# ADSP-2183xW_LPC register map
Vendor: Analog Devices; Series: ADSP-2183xW_LPC; File version: 3.0.3.517
CPU: 
Registers are 32-bit, read-write, reset 0x0 unless marked. A register's access mark holds for its fields unless they carry their own. Offsets are from the block's base; [hi:lo] are bit positions; {n}, {i} and the like mark numbered series.

## WDOG0 — Watchdog Timer Unit
Base 0x31008000
Same registers: WDOG1 0x31008800, WDOG2 0x31009000
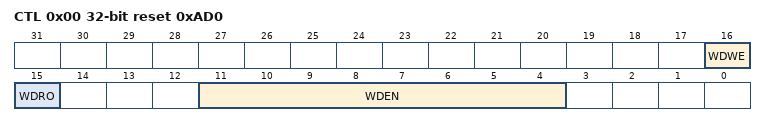
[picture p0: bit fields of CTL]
0x00 CTL reset 0xAD0 — Control Register
  [16] WDWE — Watchdog Window Event
  [15] WDRO — Watch Dog Rollover
  [11:4] WDEN — Watch Dog Enable
0x04 CNT — Count Register
  [31:0] VALUE range 0x00000000..0xFFFFFFFF — Count Value
0x08 STAT — Watchdog Timer Status Register
  [31:0] VALUE range 0x00000000..0xFFFFFFFF — Current Count Value (Status)
0x0C WIN reset 0xFFFFFFFF — Watchdog Timer Window Register
  [31:0] VALUE range 0x00000000..0xFFFFFFFF — Window Value

## OTPC0 — OTP Memory Controller
Base 0x31011000
0x04 STAT — OTP Status Register
  [14:13] ADDRERR ro — OTP Address Error
0x2C SECU_STATE reset 0x1 — OTP Security State Register
  [0] PARTLOCK ro — Part Locked
    0=OPEN (OPEN part); 1=LOCKED (Locked part)

## HADC0 — Housekeeping ADC
Base 0x31016000
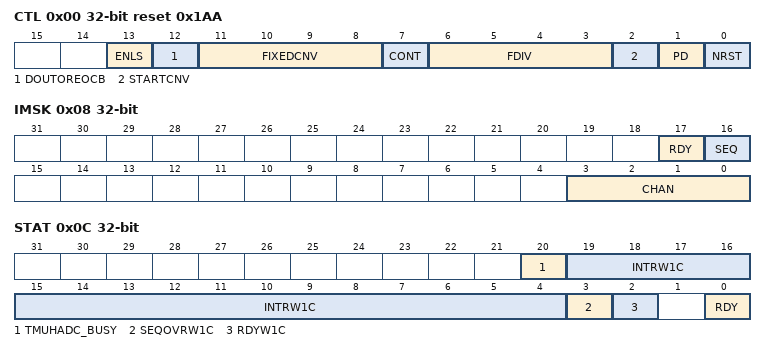
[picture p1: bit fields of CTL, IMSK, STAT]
0x00 CTL reset 0x1AA — Control Register
  [13] ENLS — Enable Level Shifters
  [12] DOUTOREOCB — Serial data on DOUT
  [11:8] FIXEDCNV range 0x00000000..0x0000000F — Fixed Conversion
  [7] CONT — Continuous Conversion
    0=ADC_CONT_FIXED (ADC converts sequence for fixed number of times); 1=ADC_CONT (ADC continuously converts given sequence)
  [6:3] FDIV range 0x00000000..0x0000000F — Frequency Divider
  [2] STARTCNV — Start conversion
  [1] PD — Power down
  [0] NRST — Reset
    0=ADC_NRESET (Reset the ADC)
0x04 CHAN_MSK reset 0xFF00 — Channel Mask Register
  [7:0] VALUE range 0x00000000..0x000000FF — Mask for Each Channel
0x08 IMSK — Interrupt Mask Register
  [17] RDY range 0x00000000..0x00000001 — Mask Interrupt when ADC Ready
  [16] SEQ — Mask Interrupt at End of Sequence
  [3:0] CHAN range 0x00000000..0x0000000F — CHAN[3:0] Channel Mask
0x0C STAT — Status Register
  [20] TMUHADC_BUSY ro — Temperature Conversion Status
  [19:4] INTRW1C wo range 0x00000000..0x0000FFFF — Conversion Complete Interrupt
  [3] SEQOVRW1C wo range 0x00000000..0x00000001 — End of Sequence Conversion
  [2] RDYW1C wo range 0x00000000..0x00000001 — Ready to Convert
  [0] RDY ro — ADC Ready
{0x10+4i} DATA[{i}] (i=0..7) — Channel Data Registers
  [11:0] VALUE ro — Converted Data

## TMU0 — Thermal monitoring unit
Base 0x31016800
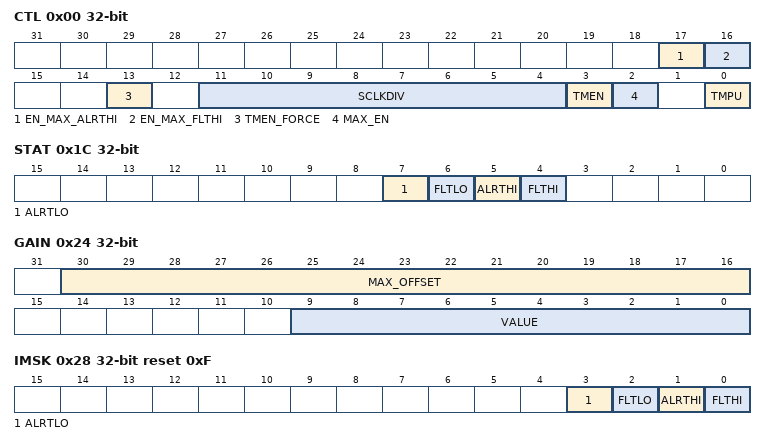
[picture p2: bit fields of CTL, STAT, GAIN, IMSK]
0x00 CTL — TMU Control Register
  [17] EN_MAX_ALRTHI range 0x00000000..0x00000001 — Enables ORing of ALERT_HIGH from max temperature with ALERT_HIGH of the default TMU sensor
  [16] EN_MAX_FLTHI range 0x00000000..0x00000001 — Enables ORing of FAULT_HIGH from max temperature with FAULT_HIGH of the default TMU sensor
  [13] TMEN_FORCE range 0x00000000..0x00000001 — Indefinite Enable
  [11:4] SCLKDIV range 0x00000000..0x000000FF — System Clock Divide
  [3] TMEN range 0x00000000..0x00000001 — Periodic Enable
  [2] MAX_EN range 0x00000000..0x00000001 — When asserted max temperature feature is enabled.
  [0] TMPU range 0x00000000..0x00000001 — TMU Enable
0x04 TEMP — Temperature Value Register
  [15:0] VALUE ro
0x08 AVG — Averaging Register
  [0] EN range 0x00000000..0x00000001 — Value
0x0C FLT_LIM_HI reset 0xFF — Fault High Limit Register
  [8:0] VALUE range 0x00000000..0x000001FF
0x10 ALRT_LIM_HI reset 0xFF — Alert High Limit Register
  [8:0] VALUE range 0x00000000..0x000001FF
0x14 FLT_LIM_LO reset 0x100 — Fault Low Limit Register
  [8:0] VALUE range 0x00000000..0x000001FF
0x18 ALRT_LIM_LO reset 0x100 — Alert Low Limit Register
  [8:0] VALUE range 0x00000000..0x000001FF
0x1C STAT — Status Register
  [7] ALRTLO ro — Alert Low
  [6] FLTLO ro — Fault Low
  [5] ALRTHI range 0x00000000..0x00000001 — Alert High
  [4] FLTHI range 0x00000000..0x00000001 — Fault High
0x20 MAX_GAIN — TRIM Register
  [25:16] VALUE range 0x00000000..0x000003FF — Control Register 2
0x24 GAIN — Gain Value Register
  [30:16] MAX_OFFSET range 0x00000000..0x00007FFF — Control Register 3
  [9:0] VALUE range 0x00000000..0x000003FF
0x28 IMSK reset 0xF — Interrupt Mask Register
  [3] ALRTLO range 0x00000000..0x00000001 — Alert Low Mask
  [2] FLTLO range 0x00000000..0x00000001 — Fault Low Mask
  [1] ALRTHI range 0x00000000..0x00000001 — Alert High Mask
  [0] FLTHI range 0x00000000..0x00000001 — Fault High Mask
0x2C OFFSET
  [14:0] VALUE range 0x00000000..0x00007FFF
0x34 CNV_BLANK reset 0x3100000 — Temperature Conversion Blank Register
  [28:24] PERIOD range 0x00000000..0x0000001F — Blanking Period
0x38 REFR_CNTR — Temperature Refresh Counter
  [5:0] VALUE range 0x00000000..0x0000003F — Refresh Period
0x44 MAX_TEMP — Debug register
  [8:0] VALUE ro — Maximum temperature value. 2's complement integer value.
